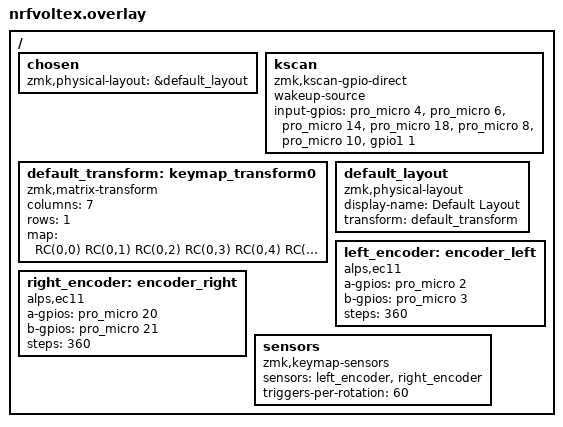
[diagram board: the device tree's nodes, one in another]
// This file was generated from a template. Edit it to match your keyboard.
// See https://zmk.dev/docs/development/hardware-integration/new-shield for more
// instructions.

#include <dt-bindings/zmk/matrix_transform.h>

#include "nrfvoltex-layouts.dtsi"

/ {
    chosen {
        zmk,physical-layout = &default_layout;
    };

    kscan: kscan {
        compatible = "zmk,kscan-gpio-direct";
        wakeup-source;
        input-gpios
            = <&pro_micro 4 (GPIO_ACTIVE_HIGH | GPIO_PULL_DOWN)>
            , <&pro_micro 6 (GPIO_ACTIVE_HIGH | GPIO_PULL_DOWN)>
            , <&pro_micro 14 (GPIO_ACTIVE_HIGH | GPIO_PULL_DOWN)>
            , <&pro_micro 18 (GPIO_ACTIVE_HIGH | GPIO_PULL_DOWN)>
            , <&pro_micro 8 (GPIO_ACTIVE_HIGH | GPIO_PULL_DOWN)>
            , <&pro_micro 10 (GPIO_ACTIVE_HIGH | GPIO_PULL_DOWN)>
            , <&gpio1 1 (GPIO_ACTIVE_HIGH | GPIO_PULL_DOWN)>
            ;
    };

    default_transform: keymap_transform0 {
        compatible = "zmk,matrix-transform";
        columns = <7>; // Length of the "col-gpios" array
        rows = <1>; // Length of the "row-gpios" array
        map = <
            RC(0,0) RC(0,1) RC(0,2) RC(0,3) RC(0,4) RC(0,5) RC(0,6)
        >;
    };

    default_layout: default_layout {
        compatible = "zmk,physical-layout";
        display-name = "Default Layout";
        transform = <&default_transform>; // Label of the matrix transform for this layout
    };

    left_encoder: encoder_left {
        compatible = "alps,ec11";
        a-gpios = <&pro_micro 2 (GPIO_ACTIVE_HIGH | GPIO_PULL_UP)>;
        b-gpios = <&pro_micro 3 (GPIO_ACTIVE_HIGH | GPIO_PULL_UP)>;
        steps = <360>;
        status = "disabled";
    };

    right_encoder: encoder_right {
        compatible = "alps,ec11";
        a-gpios = <&pro_micro 20 (GPIO_ACTIVE_HIGH | GPIO_PULL_UP)>;
        b-gpios = <&pro_micro 21 (GPIO_ACTIVE_HIGH | GPIO_PULL_UP)>;
        steps = <360>;
        status = "disabled";
    };

    sensors: sensors {
        compatible = "zmk,keymap-sensors";
        sensors = <&left_encoder &right_encoder>;
        triggers-per-rotation = <60>;
    };
};

&left_encoder {
    status = "okay";
};

&right_encoder {
    status = "okay";
};
